# STM32H7P5 register map
File version: 2.0.0
CPU: CM7 r1p2, little endian, MPU, FPU, 4 interrupt priority bits
Registers are 32-bit, read-write, reset 0x0 unless marked. A register's access mark holds for its fields unless they carry their own. Offsets are from the block's base; [hi:lo] are bit positions; {n}, {i} and the like mark numbered series; 'fields as' and 'values as' point back to an identical list.

## HRTIM1 (part 1 of 7) — HRTIM register block
Base 0x42006000
Same registers: HRTIM2 0x42007000
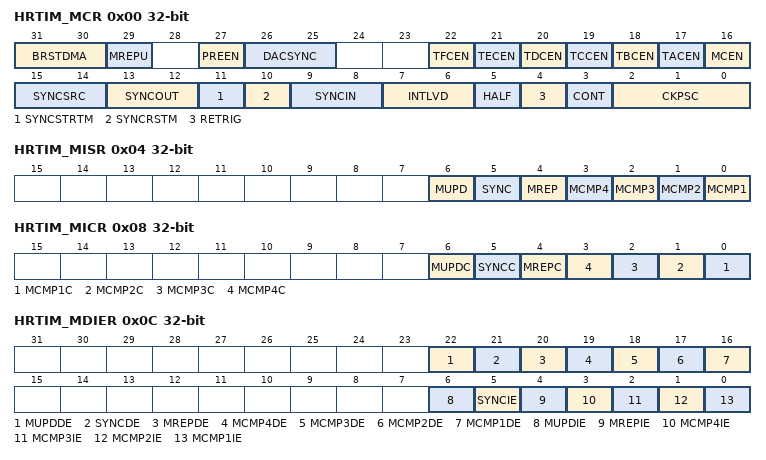
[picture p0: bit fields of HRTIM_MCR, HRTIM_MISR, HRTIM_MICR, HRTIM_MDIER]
0x00 HRTIM_MCR — HRTIM master timer control register
  [31:30] BRSTDMA — Burst DMA update
    0=Update done independently from the DMA burst transfer completion; 1=Update done when the DMA burst transfer is completed; 2=Update done on master timer roll-over following a DMA burst transfer completion. This mode only works in continuous mode.
  [29] MREPU — Master timer repetition update
    0=Update on repetition disabled; 1=Update on repetition enabled
  [27] PREEN — Preload enable
    0=Preload disabled: the write access is directly done into the active register; 1=Preload enabled: the write access is done into the preload register
  [26:25] DACSYNC — DAC synchronization
    0=No DAC trigger generated; 1=Trigger generated on hrtim_dac_trg1; 2=Trigger generated on hrtim_dac_trg2; 3=Trigger generated on hrtim_dac_trg3
  [22] TFCEN — Timer F counter enable
    0=Timer F counter disabled; 1=Timer F counter enabled
  [21] TECEN — Timer E counter enable
    0=Timer E counter disabled; 1=Timer E counter enabled
  [20] TDCEN — Timer D counter enable
    0=Timer D counter disabled; 1=Timer D counter enabled
  [19] TCCEN — Timer C counter enable
    0=Timer C counter disabled; 1=Timer C counter enabled
  [18] TBCEN — Timer B counter enable
    0=Timer B counter disabled; 1=Timer B counter enabled
  [17] TACEN — Timer A counter enable
    0=Timer A counter disabled; 1=Timer A counter enabled
  [16] MCEN — Master timer counter enable
    0=Master counter disabled; 1=Master counter enabled
  [15:14] SYNCSRC — Synchronization source
    0=Master timer start; 1=Master timer compare 1 event; 2=Timer A start/reset; 3=Timer A compare 1 event
  [13:12] SYNCOUT — Synchronization output
    0=Disabled; 1=On-chip synchronization sent to other HRTIM instances; 2=Positive pulse on HRTIM_SCOUT output (16x fless thansub>HRTIMless than/sub> clock cycles); 3=Negative pulse on HRTIM_SCOUT output (16x fless thansub>HRTIMless than/sub> clock cycles)
  [11] SYNCSTRTM — Synchronization starts master
    0=No effect on the master timer; 1=A synchronization input event starts the master timer
  [10] SYNCRSTM — Synchronization resets master
    0=No effect on the master timer; 1=A synchronization input event resets the master timer
  [9:8] SYNCIN — Synchronization input
    0=Disabled. HRTIM is not synchronized and runs in standalone mode.; 1=Internal event on hrtim_in_sync[1], from other on-chip HRTIM instances; 2=Internal event on hrtim_in_sync[2]: the HRTIM is synchronized with the on-chip timer (see Section: Synchronization input); 3=External event on hrtim_in_sync[3]: a positive pulse on HRTIM_SCIN input triggers the HRTIM
  [7:6] INTLVD — Interleaved mode
    0=Interleaved mode disabled; 1=Triple interleaved mode: when HRTIM_MPER register is written, the HRTIM_MCMP1R active register is automatically updated with HRTIM_MPER/3 value, and the HRTIM_MCMP2R active register is automatically updated with 2x (HRTIM_MPER/3) value; 2=Quad interleaved mode: when HRTIM_MPER register is written, the HRTIM_MCMP1R active register is automatically updated with HRTIM_MPER/4 value, the HRTIM_MCMP2R active register is automatically updated with HRTIM_MPER/2 value and the HRTIM_MCMP3R active register is automatically updated with 3x (HRTIM_MPER/4) value; 3=Interleaved mode disabled
  [5] HALF — Half mode
    0=Half mode disabled; 1=Half mode enabled
  [4] RETRIG — Re-triggerable mode
    0=The timer is not re-triggerable: a counter reset can be done only if the counter is stopped (period elapsed); 1=The timer is re-triggerable: a counter reset is done whatever the counter state (running or stopped)
  [3] CONT — Continuous mode
    0=The timer operates in single-shot mode and stops when it reaches the MPER value; 1=The timer operates in continuous (free-running) mode and rolls over to zero when it reaches the MPER value
  [2:0] CKPSC — Clock prescaler
0x04 HRTIM_MISR ro — HRTIM master timer interrupt status register
  [6] MUPD — Master update interrupt flag
    0=No master update interrupt occurred; 1=Master update interrupt occurred
  [5] SYNC — Sync input interrupt flag
    0=No sync input interrupt occurred; 1=Sync input interrupt occurred
  [4] MREP — Master repetition interrupt flag
    0=No master repetition interrupt occurred; 1=Master repetition interrupt occurred
  [3] MCMP4 — Master compare 4 interrupt flag
  [2] MCMP3 — Master compare 3 interrupt flag
  [1] MCMP2 — Master compare 2 interrupt flag
  [0] MCMP1 — Master compare 1 interrupt flag
    0=No master compare 1 interrupt occurred; 1=Master compare 1 interrupt occurred
0x08 HRTIM_MICR wo — HRTIM master timer interrupt clear register
  [6] MUPDC — Master update interrupt flag clear
  [5] SYNCC — Sync input interrupt flag clear
  [4] MREPC — Repetition interrupt flag clear
  [n-1] MCMP{n}C (n=1..4) — Master compare {n} interrupt flag clear
0x0C HRTIM_MDIER — HRTIM master timer DMA interrupt enable register
  [22] MUPDDE — Master update DMA request enable
    0=Master update DMA request disabled; 1=Master update DMA request enabled
  [21] SYNCDE — Sync input DMA request enable
    0=Sync input DMA request disabled; 1=Sync input DMA request enabled
  [20] MREPDE — Master repetition DMA request enable
    0=Repetition DMA request disabled; 1=Repetition DMA request enabled
  [19] MCMP4DE — Master compare 4 DMA request enable
  [18] MCMP3DE — Master compare 3 DMA request enable
  [17] MCMP2DE — Master compare 2 DMA request enable
  [16] MCMP1DE — Master compare 1 DMA request enable
    0=Compare 1 DMA request disabled; 1=Compare 1 DMA request enabled
  [6] MUPDIE — Master update interrupt enable
    0=Master update interrupts disabled; 1=Master update interrupts enabled
  [5] SYNCIE — Sync input interrupt enable
    0=Sync input interrupts disabled; 1=Sync input interrupts enabled
  [4] MREPIE — Master repetition interrupt enable
    0=Master repetition interrupt disabled; 1=Master repetition interrupt enabled
  [3] MCMP4IE — Master compare 4 interrupt enable
  [2] MCMP3IE — Master compare 3 interrupt enable
  [1] MCMP2IE — Master compare 2 interrupt enable
  [0] MCMP1IE — Master compare 1 interrupt enable
    0=Compare 1 interrupt disabled; 1=Compare 1 interrupt enabled
0x10 HRTIM_MCNTR — HRTIM master timer counter register
  [15:0] MCNT — Counter value
0x14 HRTIM_MPER reset 0xFFDF — HRTIM master timer period register
  [15:0] MPER — Master timer period value
0x18 HRTIM_MREP — HRTIM master timer repetition register
  [7:0] MREP — Master timer repetition period value
0x1C HRTIM_MCMP1R — HRTIM master timer compare 1 register
  [15:0] MCMP1 — Master timer compare 1 value
{0x1C+4i} HRTIM_MCMP{i}R (i=2..4) — HRTIM master timer compare {i} register
  [15:0] MCMP{i} — Master timer compare {i} value
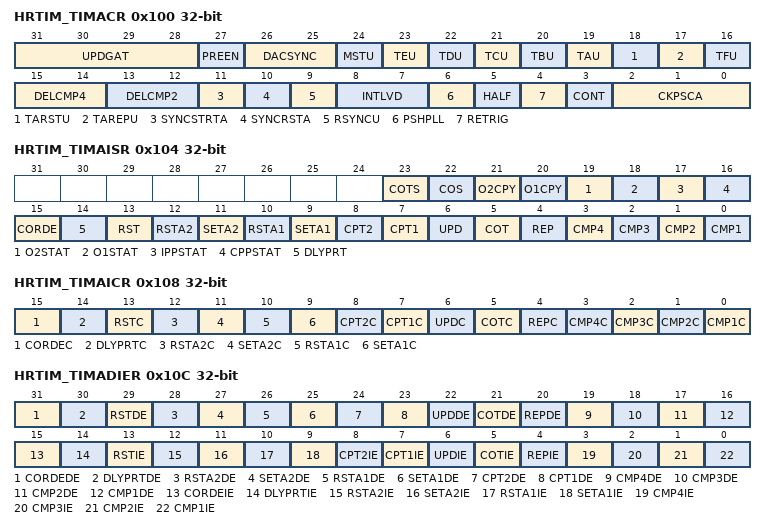
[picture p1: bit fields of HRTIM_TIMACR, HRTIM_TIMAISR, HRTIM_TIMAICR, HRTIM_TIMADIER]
0x100 HRTIM_TIMACR — HRTIM timer A control register
  [31:28] UPDGAT — Update gating
    0=The update occurs independently from the DMA burst transfer; 1=The update occurs when the DMA burst transfer is completed; 2=The update occurs on the update event following the DMA burst transfer completion; 3=The update occurs on a rising edge on hrtim_upd_en1; 4=The update occurs on a rising edge on hrtim_upd_en2; 5=The update occurs on a rising edge on hrtim_upd_en3; 6=The update occurs on the update event following a rising edge on hrtim_upd_en1; 7=The update occurs on the update event following a rising edge on hrtim_upd_en2; 8=The update occurs on the update event following a rising edge on hrtim_upd_en3
  [27] PREEN — Preload enable
    values as HRTIM_MCR.PREEN
  [26:25] DACSYNC — DAC synchronization
    values as HRTIM_MCR.DACSYNC
  [24] MSTU — Master timer update
    0=Update by master timer disabled; 1=Update by master timer enabled
  [23] TEU — Timer E update
    0=Update by timer E disabled; 1=Update by timer E enabled
  [22] TDU — Timer D update
    0=Update by timer D disabled; 1=Update by timer D enabled
  [21] TCU — Timer C update
    0=Update by timer C disabled; 1=Update by timer C enabled
  [20] TBU — Timer B update
    0=Update by timer B disabled; 1=Update by timer B enabled
  [19] TAU — Timer A update
    0=Update by timer A disabled; 1=Update by timer A enabled
  [18] TARSTU — Timer x reset update
    0=Update by timer x reset / roll-over disabled; 1=Update by timer x reset / roll-over enabled
  [17] TAREPU — Timer x repetition update
    values as HRTIM_MCR.MREPU
  [16] TFU — Timer F update
    0=Update by timer F disabled; 1=Update by timer F enabled
  [15:14] DELCMP4 — CMP4 auto-delayed mode
    0=CMP4 register is always active (standard compare mode); 1=CMP4 value is recomputed and is active following a capture 2 event; 2=CMP4 value is recomputed and is active following a capture 2 event, or is recomputed and active after Compare 1 match (timeout function if capture 2 event is missing); 3=CMP4 value is recomputed and is active following a capture 2 event, or is recomputed and active after Compare 3 match (timeout function if capture event is missing)
  [13:12] DELCMP2 — CMP2 auto-delayed mode
    0=CMP2 register is always active (standard compare mode); 1=CMP2 value is recomputed and is active following a capture 1 event; 2=CMP2 value is recomputed and is active following a capture 1 event, or is recomputed and active after compare 1 match (timeout function if capture event is missing); 3=CMP2 value is recomputed and is active following a capture 1 event, or is recomputed and active after compare 3 match (timeout function if capture event is missing)
  [11] SYNCSTRTA — Synchronization starts timer x
    0=No effect on timer x; 1=A synchronization input event starts the timer x
  [10] SYNCRSTA — Synchronization resets timer x
    0=No effect on timer x; 1=A synchronization input event resets the timer x
  [9] RSYNCU — Re-synchronized update
    0=The update coming from adjacent timers (when MSTU, TAU, TBU, TCU, TDU, TEU, TFU bit is set) or from a software update (TxSWU bit) is taken into account immediately; 1=The update coming from adjacent timers (when MSTU, TAU, TBU, TCU, TDU, TEU, TFU bit is set) or from a software update (TxSWU bit) is taken into account on the following reset/roll-over event
  [8:7] INTLVD — Interleaved mode
    0=Interleaved mode disabled; 1=Triple interleaved mode: when HRTIM_PERxR register is written, the HRTIM_CMP1xR active register is automatically updated with HRTIM_PERxR/3 value, and the HRTIM_CMP2xR active register is automatically updated with 2x (HRTIM_PERxR/3) value; 2=Quad interleaved mode: when HRTIM_PERxR register is written, the HRTIM_CMP1xR active register is automatically updated with HRTIM_PERxR/4 value, the HRTIM_CMP2xR active register is automatically updated with HRTIM_PERxR/2 value and the HRTIM_CMP3xR active register is automatically updated with 3x (HRTIM_PERxR/4) value; 3=Interleaved mode disabled
  [6] PSHPLL — Push-pull mode enable
    0=Push-pull mode disabled; 1=Push-pull mode enabled
  [5] HALF — Half mode enable
    0=Half mode disabled; 1=Half mode enabled
  [4] RETRIG — Re-triggerable mode
    0=The timer is not re-triggerable: a counter reset is done if the counter is stopped (period elapsed in single-shot mode or counter stopped in continuous mode); 1=The timer is re-triggerable: a counter reset is done whatever the counter state
  [3] CONT — Continuous mode
    0=The timer operates in single-shot mode and stops when it reaches TIMxPER value; 1=The timer operates in continuous mode and rolls over to zero when it reaches TIMxPER value
  [2:0] CKPSCA — HRTIM timer x clock prescaler
0x104 HRTIM_TIMAISR ro — HRTIM timer A interrupt status register
  [23] COTS — Crossbar Override Trigger status
    0=Crossbar Override trigger is inactive; 1=Crossbar Override trigger is active
  [22] COS — Crossbar Override status
    0=Crossbar Override is inactive (crossbar is active); 1=Crossbar Override is active
  [21] O2CPY — Output 2 copy
    0=Output 2 is inactive; 1=Output 2 is active
  [20] O1CPY — Output 1 copy
    0=Output 1 is inactive; 1=Output 1 is active
  [19] O2STAT — Output 2 status
    0=Output 2 was inactive; 1=Output 2 was active
  [18] O1STAT — Output 1 status
    0=Output 1 was inactive; 1=Output 1 was active
  [17] IPPSTAT — Idle push-pull Status
    0=Protection occurred when the output 1 was active and output 2 forced inactive; 1=Protection occurred when the output 2 was active and output 1 forced inactive
  [16] CPPSTAT — Current push-pull status
    0=Signal applied on output 1 and output 2 forced inactive; 1=Signal applied on output 2 and output 1 forced inactive
  [15] CORDE — Crossbar Override Rearm Delay Elapsed flag
    0=No Crossbar override rearm delay elapsed interrupt occurred; 1=Crossbar override rearm delay elapsed interrupt occurred
  [14] DLYPRT — Delayed protection flag
    0=No delayed protection interrupt occurred; 1=Delayed Idle or balanced Idle mode entry occurred
  [13] RST — Reset and/or roll-over interrupt flag
    0=No TIMx counter reset/roll-over interrupt occurred; 1=TIMX counter reset/roll-over interrupt occurred
  [12] RSTA2 — Output 2 reset interrupt flag timer x
  [11] SETA2 — Output 2 set interrupt flag timer x
  [10] RSTA1 — Output 1 reset interrupt flag timer x
    0=No Tx1 output reset interrupt occurred; 1=Tx1 output reset interrupt occurred
  [9] SETA1 — Output 1 set interrupt flag timer x
    0=No Tx1 output set interrupt occurred; 1=Tx1 output set interrupt occurred
  [8] CPT2 — Capture 2 interrupt flag
  [7] CPT1 — Capture 1 interrupt flag
    0=No timer x capture 1 interrupt occurred; 1=Timer x capture 1 interrupt occurred
  [6] UPD — Update interrupt flag
    0=No timer x update interrupt occurred; 1=Timer x update interrupt occurred
  [5] COT — Crossbar Override Trigger flag
    0=No Crossbar override trigger interrupt occurred; 1=Crossbar override trigger interrupt occurred
  [4] REP — Repetition interrupt flag
    0=No timer x repetition interrupt occurred; 1=Timer x repetition interrupt occurred
  [3] CMP4 — Compare 4 interrupt flag
  [2] CMP3 — Compare 3 interrupt flag
  [1] CMP2 — Compare 2 interrupt flag
  [0] CMP1 — Compare 1 interrupt flag
    0=No compare 1 interrupt occurred; 1=Compare 1 interrupt occurred
0x108 HRTIM_TIMAICR wo — HRTIM timer A interrupt clear register
  [15] CORDEC — Crossbar Override Rearm Delay Elapsed flag clear
  [14] DLYPRTC — Delayed protection flag clear
  [13] RSTC — Reset interrupt flag clear
  [12] RSTA2C — Output 2 reset flag clear timer x
  [11] SETA2C — Output 2 set flag clear timer x
  [10] RSTA1C — Output 1 reset flag clear timer x
  [9] SETA1C — Output 1 set flag clear timer x
  [8] CPT2C — Capture 2 interrupt flag clear
  [7] CPT1C — Capture 1 interrupt flag clear
  [6] UPDC — Update interrupt flag clear
  [5] COTC — Crossbar Override Trigger flag clear
  [4] REPC — Repetition interrupt flag clear
  [n-1] CMP{n}C (n=1..4) — Compare {n} interrupt flag clear
0x10C HRTIM_TIMADIER — HRTIM timer A DMA interrupt enable register
  [31] CORDEDE — Crossbar override rearm delay elapsed DMA request enable
    0=Crossbar override rearm delay elapsed DMA request disabled; 1=Crossbar override rearm delay elapsed DMA request enabled
  [30] DLYPRTDE — Delayed protection DMA request enable
    0=Delayed protection DMA request disabled; 1=Delayed protection DMA request enabled
  [29] RSTDE — Reset/roll-over DMA request enable
    0=Timer x counter reset/roll-over DMA request disabled; 1=Timer x counter reset/roll-over DMA request enabled
  [28] RSTA2DE — Output 2 reset DMA request enable timer x
  [27] SETA2DE — Output 2 set DMA request enable timer x
  [26] RSTA1DE — Output 1 reset DMA request enable timer x
    0=Tx1 output reset DMA request disabled; 1=Tx1 output reset DMA request enabled
  [25] SETA1DE — Output 1 set DMA request enable timer x
    0=Tx1 output set DMA request disabled; 1=Tx1 output set DMA request enabled
  [24] CPT2DE — Capture 2 DMA request enable
  [23] CPT1DE — Capture 1 DMA request enable
    0=Capture 1 DMA request disabled; 1=Capture 1 DMA request enabled
  [22] UPDDE — Update DMA request enable
    0=Update DMA request disabled; 1=Update DMA request enabled
  [21] COTDE — Crossbar Override Trigger DMA request enable
    0=Crossbar Override Trigger DMA request disabled; 1=Crossbar Override Trigger DMA request enabled
  [20] REPDE — Repetition DMA request enable
    values as HRTIM_MDIER.MREPDE
  [19] CMP4DE — Compare 4 DMA request enable
  [18] CMP3DE — Compare 3 DMA request enable
  [17] CMP2DE — Compare 2 DMA request enable
  [16] CMP1DE — Compare 1 DMA request enable
    values as HRTIM_MDIER.MCMP1DE
  [15] CORDEIE — Crossbar override rearm delay elapsed interrupt enable
    0=Crossbar override rearm delay elapsed interrupts disabled; 1=Crossbar override rearm delay elapsed interrupts enabled
  [14] DLYPRTIE — Delayed protection interrupt enable
    0=Delayed protection interrupts disabled; 1=Delayed protection interrupts enabled
  [13] RSTIE — Reset/roll-over interrupt enable
    0=Timer x counter reset/roll-over interrupt disabled; 1=Timer x counter reset/roll-over interrupt enabled
  [12] RSTA2IE — Output 2 reset interrupt enable timer x
  [11] SETA2IE — Output 2 set interrupt enable timer x
  [10] RSTA1IE — Output 1 reset interrupt enable timer x
    0=Tx1 output reset interrupts disabled; 1=Tx1 output reset interrupts enabled
  [9] SETA1IE — Output 1 set interrupt enable timer x
    0=Tx1 output set interrupts disabled; 1=Tx1 output set interrupts enabled
  [8] CPT2IE — Capture interrupt enable
  [7] CPT1IE — Capture interrupt enable
    0=Capture 1 interrupts disabled; 1=Capture 1 interrupts enabled
  [6] UPDIE — Update interrupt enable
    0=Update interrupts disabled; 1=Update interrupts enabled
  [5] COTIE — Crossbar Override Trigger interrupt enable
    0=Crossbar Override Trigger interrupts disabled; 1=Crossbar Override Trigger enabled
  [4] REPIE — Repetition interrupt enable
    0=Repetition interrupts disabled; 1=Repetition interrupts enabled
  [3] CMP4IE — Compare 4 interrupt enable
  [2] CMP3IE — Compare 3 interrupt enable
  [1] CMP2IE — Compare 2 interrupt enable
  [0] CMP1IE — Compare 1 interrupt enable
    values as HRTIM_MDIER.MCMP1IE
0x110 HRTIM_CNTAR — HRTIM timer A counter register
  [15:0] CNTA — Timer x counter value
0x114 HRTIM_PERAR reset 0xFFDF — HRTIM timer A period register
  [15:0] PERA — Timer x period value
0x118 HRTIM_REPAR — HRTIM timer A repetition register
  [7:0] REPA — Timer x repetition period value
0x11C HRTIM_CMP1AR — HRTIM timer A compare 1 register
  [15:0] CMP1A — Timer x compare 1 value
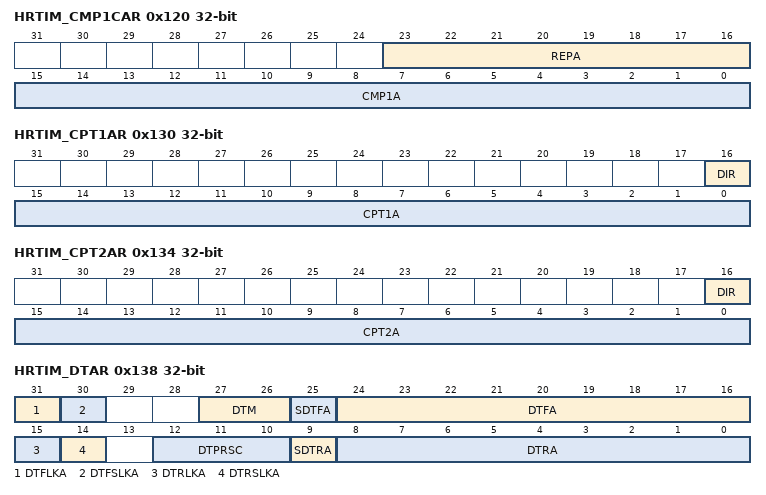
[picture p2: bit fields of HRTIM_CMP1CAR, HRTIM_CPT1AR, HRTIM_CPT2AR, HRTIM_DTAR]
0x120 HRTIM_CMP1CAR — HRTIM timer A compare 1 compound register
  [23:16] REPA — Timer x repetition value aliased from HRTIM_REPx register
  [15:0] CMP1A — Timer x compare 1 value
{0x11C+4i} HRTIM_CMP{i}AR (i=2..4) — HRTIM timer A compare {i} register
  [15:0] CMP{i}A — Timer x compare {i} value
0x130 HRTIM_CPT1AR ro — HRTIM timer A capture 1 register
  [16] DIR — Timer x capture 1 direction status
    0=timer is up-counting; 1=timer is down-counting
  [15:0] CPT1A — Timer x capture 1 value
0x134 HRTIM_CPT2AR ro — HRTIM timer A capture 2 register
  [16] DIR — Timer x capture 1 direction status
    0=timer is up-counting; 1=timer is down-counting
  [15:0] CPT2A — Timer x capture 2 value
0x138 HRTIM_DTAR rw-once — HRTIM timer A deadtime register
  [31] DTFLKA — Deadtime falling lock timer x
    0=Deadtime falling value and sign is writable; 1=Deadtime falling value and sign is read-only
  [30] DTFSLKA — Deadtime falling sign lock timer x
    0=Deadtime falling sign is writable; 1=Deadtime falling sign is read-only
  [27:26] DTM rw — Deadtime mode
    0=Deadtime complementary mode; 1=Deadtime insertion mode; 2=Deadtime insertion and disarm mode
  [25] SDTFA rw — Sign deadtime falling value timer x
    0=Positive deadtime on falling edge; 1=Negative deadtime on falling edge
  [24:16] DTFA rw — Deadtime falling value timer x
  [15] DTRLKA — Deadtime rising lock timer x
    0=Deadtime rising value and sign is writable; 1=Deadtime rising value and sign is read-only
  [14] DTRSLKA — Deadtime rising sign lock timer x
    0=Deadtime rising sign is writable; 1=Deadtime rising sign is read-only
  [12:10] DTPRSC rw — Deadtime prescaler
  [9] SDTRA rw — Sign deadtime rising value timer x
    0=Positive deadtime on rising edge; 1=Negative deadtime on rising edge
  [8:0] DTRA rw — Deadtime rising value timer x
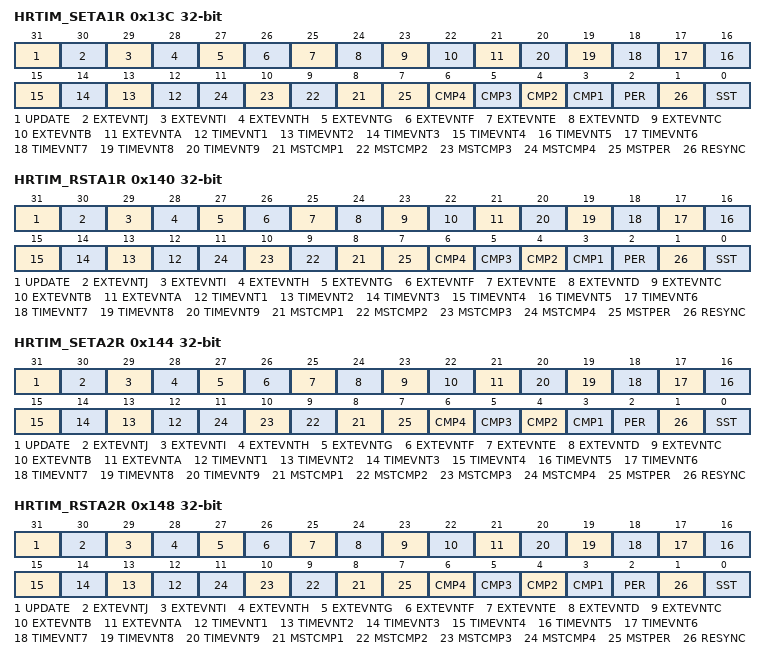
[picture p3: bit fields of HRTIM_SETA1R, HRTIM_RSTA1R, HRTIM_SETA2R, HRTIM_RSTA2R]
0x13C HRTIM_SETA1R — HRTIM timer A output 1 set register
  [31] UPDATE — Registers update (transfer from preload register to active register)
  [30] EXTEVNTJ — External event J
  [29] EXTEVNTI — External event I
  [28] EXTEVNTH — External event H
  [27] EXTEVNTG — External event G
  [26] EXTEVNTF — External event F
  [25] EXTEVNTE — External event E
  [24] EXTEVNTD — External event D
  [23] EXTEVNTC — External event C
  [22] EXTEVNTB — External event B
  [21] EXTEVNTA — External event A
  [n+11] TIMEVNT{n} (n=1..9) — Timer event {n}
  [n+7] MSTCMP{n} (n=1..4) — Master compare {n}
  [7] MSTPER — Master period
  [n+2] CMP{n} (n=1..4) — Timer x compare {n}
  [2] PER — Timer x period
  [1] RESYNC — Timer A resynchronization
  [0] SST — Software set trigger
0x140 HRTIM_RSTA1R — HRTIM timer A output 1 reset register
  fields as HRTIM_SETA1R
0x144 HRTIM_SETA2R — HRTIM timer A output 2 set register
  fields as HRTIM_SETA1R
0x148 HRTIM_RSTA2R — HRTIM timer A output 2 reset register
  fields as HRTIM_SETA1R
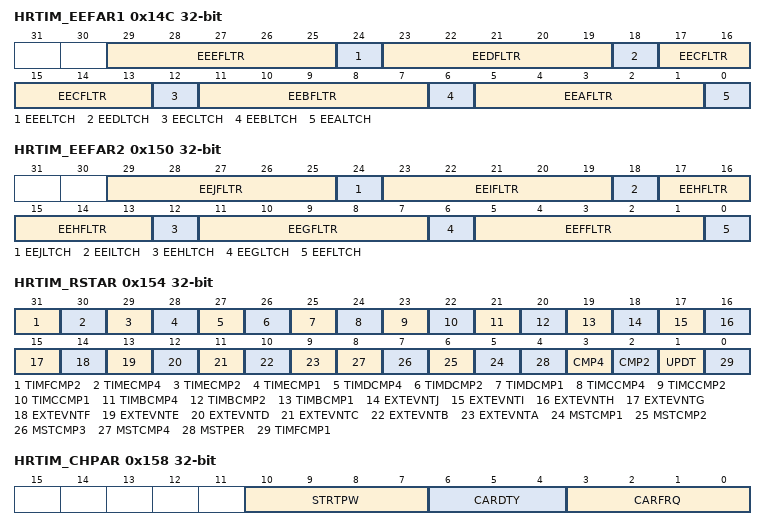
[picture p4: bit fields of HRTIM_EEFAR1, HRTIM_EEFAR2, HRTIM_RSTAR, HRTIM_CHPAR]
0x14C HRTIM_EEFAR1 — HRTIM timer A external event filtering register 1
  [29:25] EEEFLTR — External event E filter
  [24] EEELTCH — External event E latch
  [23:19] EEDFLTR — External event D filter
  [18] EEDLTCH — External event D latch
  [17:13] EECFLTR — External event C filter
  [12] EECLTCH — External event C latch
  [11:7] EEBFLTR — External event B filter
  [6] EEBLTCH — External event B latch
  [5:1] EEAFLTR — External event A filter
    0=No filtering; 1=Blanking from counter reset/roll-over to compare 1; 2=Blanking from counter reset/roll-over to compare 2 in up-counting mode (UDM bit reset); 3=Blanking from counter reset/roll-over to compare 3; 4=Blanking from counter reset/roll-over to compare 4 in up-counting mode (UDM bit reset); 13=Windowing from counter reset/roll-over to compare 2 in up-counting mode (UDM bit reset); 14=Windowing from counter reset/roll-over to compare 3 in up-counting mode (UDM bit reset); 15=Windowing from another timing unit: TIMWIN source (see Table234 for details) in up-counting mode (UDM bit reset); 16=Blanking from compare 1 to counter reset/roll-over (UDM bit reset).In up-down counting mode (UDM bit set): blanking from compare 1 during down-counting to compare 2 during the following up-counting phase; 17=Blanking from compare 2 to counter reset/roll-over (UDM bit reset).In up-down counting mode (UDM bit set): blanking from CMP1 (down-counting) to CMP2 (down-counting); 18=Blanking from compare 1 to compare 2 (UDM bit reset). In up-down counting mode (UDM bit set): blanking from CMP1 (up-counting) to CMP2 (down-counting.; 19=Blanking from compare 3 to compare 4 (UDM bit reset). In up-down counting mode (UDM bit set): blanking from CMP3 (up-counting) to CMP4 (down-counting).; 20=Windowing from compare 1 to counter reset/roll-over. In up-down counting mode (UDM bit set), the reset/roll-over event is conditioned to the ROM[1:0] bitfield setting; 21=Windowing from compare 2 to counter reset/roll-over. In up-down counting mode (UDM bit set), the reset/roll-over event is conditioned to the ROM[1:0] bitfield setting; 22=Windowing from compare 1 to compare 2 (UDM bit reset). In up-down counting mode (UDM bit set): windowing from CMP1 (up-counting) to CMP2 (down-counting).; 23=Windowing from compare 3 to compare 4 (UDM bit reset). In up-down counting mode (UDM bit set): windowing from compare 3 during down-counting to compare 4 during the following up-counting phase; 24=TIMWIN2 source (see Table234 for details). In up-down counting mode (UDM bit set), the reset/roll-over event is conditioned to the ROM[1:0] bitfield setting; 25=TIMWIN3 source (see Table234 for details); 26=Blanking from Period Event to Compare 1 In up-down counting mode (UDM bit set), the reset/roll-over event is conditioned to the ROM[1:0] bitfield setting; 27=Blanking from Period Event to Compare 2 In up-down counting mode (UDM bit set), the reset/roll-over event is conditioned to the ROM[1:0] bitfield setting
  [0] EEALTCH — External event A latch
    0=Event A is ignored if it happens during a blank, or passed through during a window; 1=Event A is latched and delayed till the end of the blanking or windowing period
0x150 HRTIM_EEFAR2 — HRTIM timer A external event filtering register 2
  [29:25] EEJFLTR — External event J filter
  [24] EEJLTCH — External event J latch
  [23:19] EEIFLTR — External event I filter
  [18] EEILTCH — External event I latch
  [17:13] EEHFLTR — External event H filter
  [12] EEHLTCH — External event H latch
  [11:7] EEGFLTR — External event G filter
  [6] EEGLTCH — External event G latch
  [5:1] EEFFLTR — External event F filter
  [0] EEFLTCH — External event F latch
0x154 HRTIM_RSTAR — HRTIM timer A reset register
  [31] TIMFCMP2 — Timer F compare 2
  [30] TIMECMP4 — Timer E compare 4
  [29] TIMECMP2 — Timer E compare 2
  [28] TIMECMP1 — Timer E compare 1
  [27] TIMDCMP4 — Timer D compare 4
  [26] TIMDCMP2 — Timer D compare 2
  [25] TIMDCMP1 — Timer D compare 1
  [24] TIMCCMP4 — Timer C compare 4
  [23] TIMCCMP2 — Timer C compare 2
  [22] TIMCCMP1 — Timer C compare 1
  [21] TIMBCMP4 — Timer B compare 4
  [20] TIMBCMP2 — Timer B compare 2
  [19] TIMBCMP1 — Timer B compare 1
  [18] EXTEVNTJ — External event J
  [17] EXTEVNTI — External event I
  [16] EXTEVNTH — External event H
  [15] EXTEVNTG — External event G
  [14] EXTEVNTF — External event F
  [13] EXTEVNTE — External event E
  [12] EXTEVNTD — External event D
  [11] EXTEVNTC — External event C
  [10] EXTEVNTB — External event B
  [9] EXTEVNTA — External event A
  [n+4] MSTCMP{n} (n=1..4) — Master compare {n}
  [4] MSTPER — Master timer period
  [3] CMP4 — Timer A compare 4 reset
  [2] CMP2 — Timer A compare 2 reset
  [1] UPDT — Timer A update reset
  [0] TIMFCMP1 — Timer F compare 1
0x158 HRTIM_CHPAR — HRTIM timer A chopper register
  [10:7] STRTPW — Timer x start pulsewidth
    0=40 ns (1/25 MHz); 15=640 ns (16/25 MHz)
  [6:4] CARDTY — Timer x chopper duty cycle value
    0=0/8 (i.e. only 1st pulse is present); 7=7/8
  [3:0] CARFRQ — Timer x carrier frequency value
    0=25 MHz (fless thansub>HRTIMless than/sub>/ 16); 15=1.5625 MHz (fless thansub>HRTIMless than/sub> / 256)
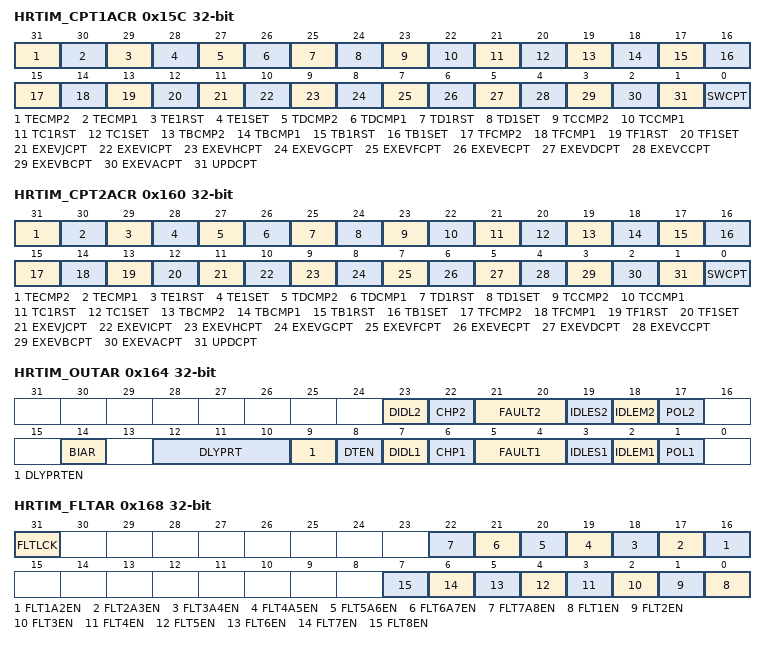
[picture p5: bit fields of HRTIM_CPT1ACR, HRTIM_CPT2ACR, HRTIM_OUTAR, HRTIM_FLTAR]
0x15C HRTIM_CPT1ACR — HRTIM timer A capture 1 control register
  [31] TECMP2 — Timer E compare 2
  [30] TECMP1 — Timer E compare 1
  [29] TE1RST — Timer E output 1 reset
  [28] TE1SET — Timer E output 1 set
  [27] TDCMP2 — Timer D compare 2
  [26] TDCMP1 — Timer D compare 1
  [25] TD1RST — Timer D output 1 reset
  [24] TD1SET — Timer D output 1 set
  [23] TCCMP2 — Timer C compare 2
  [22] TCCMP1 — Timer C compare 1
  [21] TC1RST — Timer C output 1 reset
  [20] TC1SET — Timer C output 1 set
  [19] TBCMP2 — Timer B compare 2
  [18] TBCMP1 — Timer B compare 1
  [17] TB1RST — Timer B output 1 reset
  [16] TB1SET — Timer B output 1 set
  [15] TFCMP2 — Timer E compare 2
  [14] TFCMP1 — Timer F compare 1
  [13] TF1RST — Timer F output 1 reset
  [12] TF1SET — Timer F output 1 set
  [11] EXEVJCPT — External event J capture
  [10] EXEVICPT — External event I capture
  [9] EXEVHCPT — External event H capture
  [8] EXEVGCPT — External event G capture
  [7] EXEVFCPT — External event F capture
  [6] EXEVECPT — External event E capture
  [5] EXEVDCPT — External event D capture
  [4] EXEVCCPT — External event C capture
  [3] EXEVBCPT — External event B capture
  [2] EXEVACPT — External event A capture
    0=No action; 1=The external event A triggers the capture 1
  [1] UPDCPT — Update capture
    0=No action; 1=The update event triggers the capture 1
  [0] SWCPT — Software capture
    0=No action; 1=This bit forces the capture 1 by software. This bit is set only, reset by hardware.
0x160 HRTIM_CPT2ACR — HRTIM timer A capture 2 control register
  [31] TECMP2 — Timer E compare 2
  [30] TECMP1 — Timer E compare 1
  [29] TE1RST — Timer E output 1 reset
  [28] TE1SET — Timer E output 1 set
  [27] TDCMP2 — Timer D compare 2
  [26] TDCMP1 — Timer D compare 1
  [25] TD1RST — Timer D output 1 reset
  [24] TD1SET — Timer D output 1 set
  [23] TCCMP2 — Timer C compare 2
  [22] TCCMP1 — Timer C compare 1
  [21] TC1RST — Timer C output 1 reset
  [20] TC1SET — Timer C output 1 set
  [19] TBCMP2 — Timer B compare 2
  [18] TBCMP1 — Timer B compare 1
  [17] TB1RST — Timer B output 1 reset
  [16] TB1SET — Timer B output 1 set
  [15] TFCMP2 — Timer E compare 2
  [14] TFCMP1 — Timer F compare 1
  [13] TF1RST — Timer F output 1 reset
  [12] TF1SET — Timer F output 1 set
  [11] EXEVJCPT — External event J capture
  [10] EXEVICPT — External event I capture
  [9] EXEVHCPT — External event H capture
  [8] EXEVGCPT — External event G capture
  [7] EXEVFCPT — External event F capture
  [6] EXEVECPT — External event E capture
  [5] EXEVDCPT — External event D capture
  [4] EXEVCCPT — External event C capture
  [3] EXEVBCPT — External event B capture
  [2] EXEVACPT — External event A capture
    0=No action; 1=The external event A triggers the capture 2
  [1] UPDCPT — Update capture
    0=No action; 1=The update event triggers the capture 2
  [0] SWCPT — Software capture
    0=No action; 1=This bit forces the capture 2 by software. This bit is set only, reset by hardware.
0x164 HRTIM_OUTAR — HRTIM timer A output register
  [23] DIDL2 — Output 2 deadtime upon burst mode Idle entry
    0=The programmed Idle state is applied immediately to the output 2; 1=Deadtime (inactive level) is inserted on output 2 before entering the idle mode. The deadtime value is set by DTFx[8:0].
  [22] CHP2 — Output 2 chopper enable
    0=Output signal is not altered; 1=Output signal is chopped by a carrier signal
  [21:20] FAULT2 — Output 2 fault state
    0=No action: the output is not affected by the fault input and stays in run mode; 1=Active; 2=Inactive; 3=High-Z
  [19] IDLES2 — Output 2 idle state
    0=Inactive; 1=Active
  [18] IDLEM2 — Output 2 idle mode
    0=No action: the output is not affected by the burst mode operation; 1=The output is in idle state when requested by the burst mode controller
  [17] POL2 — Output 2 polarity
    0=Positive polarity (output active high); 1=Negative polarity (output active low)
  [14] BIAR — Balanced Idle Automatic Resume
    0=Disabled; 1=Enabled
  [12:10] DLYPRT — Delayed protection
    0=Output 1 delayed idle on external event H; 1=Output 2 delayed idle on external event H; 2=Output 1 and output 2 delayed idle on external event H; 3=Balanced idle on external event H; 4=Output 1 delayed idle on external event I; 5=Output 2 delayed idle on external event I; 6=Output 1 and output 2 delayed idle on external event I; 7=Balanced idle on external event I
  [9] DLYPRTEN — Delayed protection enable
    0=No action; 1=Delayed protection is enabled, as per DLYPRT[2:0] bits
  [8] DTEN — Deadtime enable
    0=Output 1 and output 2 signals are independent; 1=Deadtime is inserted between output 1 and output 2 (reference signal is output 1 signal generator)
  [7] DIDL1 — Output 1 deadtime upon burst mode idle entry
    0=The programmed idle state is applied immediately to the output 1; 1=Deadtime (inactive level) is inserted on output 1 before entering the idle mode. The deadtime value is set by DTRx[8:0].
  [6] CHP1 — Output 1 chopper enable
    values as CHP2
  [5:4] FAULT1 — Output 1 fault state
    values as FAULT2
  [3] IDLES1 — Output 1 Idle State
    0=Inactive; 1=Active
  [2] IDLEM1 — Output 1 Idle mode
    values as IDLEM2
  [1] POL1 — Output 1 polarity
    values as POL2
0x168 HRTIM_FLTAR rw-once — HRTIM timer A fault register
  [31] FLTLCK — Fault sources lock
    0=FLT1EN..FLT6EN bits are read/write; 1=FLT1EN..FLT6EN bits are read only
  [n+15] FLT{n}A{n+1}EN rw (n=1..7) — Fault {n} AND Fault {n+1} enable
    0=Fault {n} AND Fault {n+1} ignored; 1=HRTIM outputs disabled when both Fault {n} AND Fault {n+1} inputs are active
  [n-1] FLT{n}EN rw (n=1..8) — Fault {n} enable
    0=Fault {n} input ignored; 1=Fault {n} input is active and disables HRTIM outputs
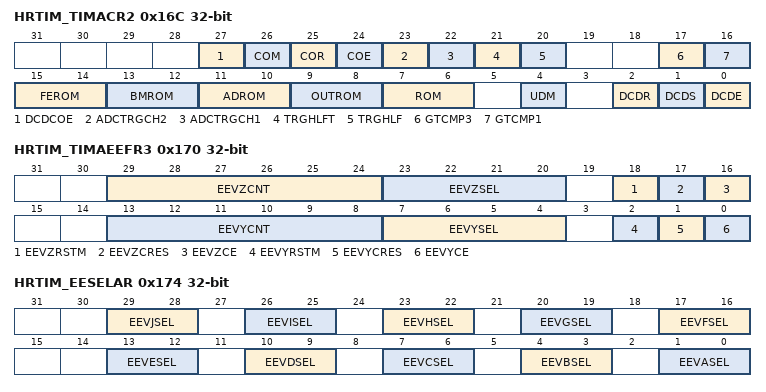
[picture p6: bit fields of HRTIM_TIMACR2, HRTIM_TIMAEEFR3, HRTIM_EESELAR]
0x16C HRTIM_TIMACR2 — HRTIM timer A control register 2
  [27] DCDCOE — Dual channel DAC crossbar override enable
    0=Dual Channel DAC Crossbar Override disabled; 1=Dual Channel DAC Crossbar Override enabled
  [26] COM — Crossbar override mode
    0=Cycle-by-cycle mode; 1=latched mode
  [25] COR wo — Crossbar override rearm
  [24] COE — Crossbar override enable
    0=Crossbar override disabled; 1=Crossbar override enabled
  [23] ADCTRGCH2 — ADC trigger for channel 2
    0=ADC triggers generated for both Channel 1 and Channel 2 active phases; 1=ADC triggers generated when Channel 2 is active (in push-pull mode)
  [22] ADCTRGCH1 — ADC trigger for channel 1
    0=ADC triggers generated for both Channel 1 and Channel 2 active phases; 1=ADC triggers generated when Channel 1 is active (in push-pull mode)
  [21] TRGHLFT — Triggered-half timeout mode
    0=No timeout event generated; 1=timeout event generated. When the counter matches the PER value, the CMP2 register takes PER/2 value.
  [20] TRGHLF — Triggered-half mode
    0=CMP2 register is written by the user only (standard compare mode); 1=CMP2 value is set by hardware as soon as a capture 1 event occurs. It is loaded with the (capture1 divided by 2) value. The initial value can be written by the user (as long as TRGHLF is
  [17] GTCMP3 — Greater than compare 3 PWM mode
    0=The compare 3 event is generated when the counter is equal to the compare value (compare match mode); 1=The compare 3 event is generated when the counter is greater than the compare value. If the compare value is changed on-the-fly, the new compare value is compared with the current counter value and an output SET or RESET can be generated.
  [16] GTCMP1 — Greater than compare 1 PWM mode
    0=The compare 1 event is generated when the counter is equal to the compare value (compare match mode); 1=The compare 1 event is generated when the counter is greater than the compare value. If the compare value is changed on-the-fly, the new compare value is compared with the current counter value and an output SET or RESET can be generated.
  [15:14] FEROM — Fault and event roll-over mode
    0=Event generated when the counter is equal to 0 or to HRTIM_PERxR value; 1=Event generated when the counter is equal to 0; 2=Event generated when the counter is equal to HRTIM_PERxR
  [13:12] BMROM — Burst mode roll-over mode
    values as FEROM
  [11:10] ADROM — ADC roll-over mode
    values as FEROM
  [9:8] OUTROM — Output roll-over mode
    values as FEROM
  [7:6] ROM — Roll-over mode
    values as FEROM
  [4] UDM — Up-Down mode
    0=The counter is operating in up-counting mode; 1=The counter is operating in up-down counting mode
  [2] DCDR — Dual channel DAC reset trigger
    0=The trigger is generated on counter reset or roll-over event; 1=The trigger is generated on output 1 set event
  [1] DCDS — Dual channel DAC Step trigger
    0=The trigger is generated on compare 2 event; 1=The trigger is generated on output 1 reset event
  [0] DCDE — Dual channel DAC trigger enable
    0=Dual channel DAC trigger disabled; 1=Dual channel DAC trigger enabled
0x170 HRTIM_TIMAEEFR3 — HRTIM timer A external event filtering register 3
  [29:24] EEVZCNT — External event Z counter
  [23:20] EEVZSEL — External event Z selection
    0=External event A is used as external event Z source; 1=External event B is used as external event Z source
  [18] EEVZRSTM — External event Z reset mode
    0=External event counter Z is reset on each reset / roll-over event; 1=External event counter Z is reset on each reset / roll-over event only if no event occurs during last counting period
  [17] EEVZCRES — External event Z counter reset
    0=No action; 1=External event counter Z counter is reset
  [16] EEVZCE — External event Z counter enable
    0=External event Z counter disabled; 1=External event Z counter enabled
  [13:8] EEVYCNT — External event Y counter
  [7:4] EEVYSEL — External event Y Selection
    0=External event A is used as external event Y source; 1=External event B is used as external event Y source
  [2] EEVYRSTM — External event Y reset mode
    0=External event counter Y is reset on each reset / roll-over event; 1=External event counter Y is reset on each reset / roll-over event only if no event occurs during last counting period
  [1] EEVYCRES — External event Y counter reset
    0=No action; 1=External event counter Y is reset
  [0] EEVYCE — External event Y counter enable
    0=External event Y counter disabled; 1=External event Y counter enabled
0x174 HRTIM_EESELAR — HRTIM timer A external event selection register
  [29:28] EEVJSEL — External event J selection
    0=EEVJ is connected to EEV10; 1=EEVJ is connected to EEV14; 2=EEVJ is connected to (EEV10 AND EEV11); 3=EEVJ is connected to (EEV10 AND EEV14)
  [26:25] EEVISEL — External event I selection
    0=EEVI is connected to EEV9; 1=EEVI is connected to EEV13; 2=EEVI is connected to (EEV9 AND EEV10); 3=EEVI is connected to (EEV9 AND EEV13)
  [23:22] EEVHSEL — External event H selection
    0=EEVH is connected to EEV8; 1=EEVH is connected to EEV12; 2=EEVH is connected to (EEV8 AND EEV9); 3=EEVH is connected to (EEV8 AND EEV12)
  [20:19] EEVGSEL — External event G selection
    0=EEVG is connected to EEV7; 1=EEVG is connected to EEV11; 2=EEVG is connected to (EEV7 AND EEV8); 3=EEVG is connected to (EEV7 AND EEV11)
  [17:16] EEVFSEL — External event F selection
    0=EEVF is connected to EEV6; 1=EEVF is connected to EEV16; 2=EEVF is connected to (EEV6 AND EEV7); 3=EEVF is connected to (EEV6 AND EEV16)
  [13:12] EEVESEL — External event E selection
    0=EEVE is connected to EEV5; 1=EEVE is connected to EEV15; 2=EEVE is connected to (EEV5 AND EEV6); 3=EEVE is connected to (EEV5 AND EEV15)
  [10:9] EEVDSEL — External event D selection
    0=EEVD is connected to EEV4; 1=EEVD is connected to EEV14; 2=EEVD is connected to (EEV4 AND EEV5); 3=EEVD is connected to (EEV4 AND EEV14)
  [7:6] EEVCSEL — External event C selection
    0=EEVC is connected to EEV3; 1=EEVC is connected to EEV13; 2=EEVC is connected to (EEV3 AND EEV4); 3=EEVC is connected to (EEV3 AND EEV13)
  [4:3] EEVBSEL — External event B selection
    0=EEVB is connected to EEV2; 1=EEVB is connected to EEV12; 2=EEVB is connected to (EEV2 AND EEV3); 3=EEVB is connected to (EEV2 AND EEV12)
  [1:0] EEVASEL — External event A selection
    0=EEVA is connected to EEV1; 1=EEVA is connected to EEV11; 2=EEVA is connected to (EEV1 AND EEV2); 3=EEVA is connected to (EEV1 AND EEV11)
